# SAMA7G54D1G device description
Architecture: CORTEX-A7; Family: SAMA; Series: SAMA7G
Registers are 32-bit, read-write, reset 0x0 unless marked. A register's access mark holds for its fields unless they carry their own. Offsets are from the block's base; [hi:lo] are bit positions; {n}, {i} and the like mark numbered series.

## SHA — Secure Hash Algorithm
Instances: SHA 0xE1814000
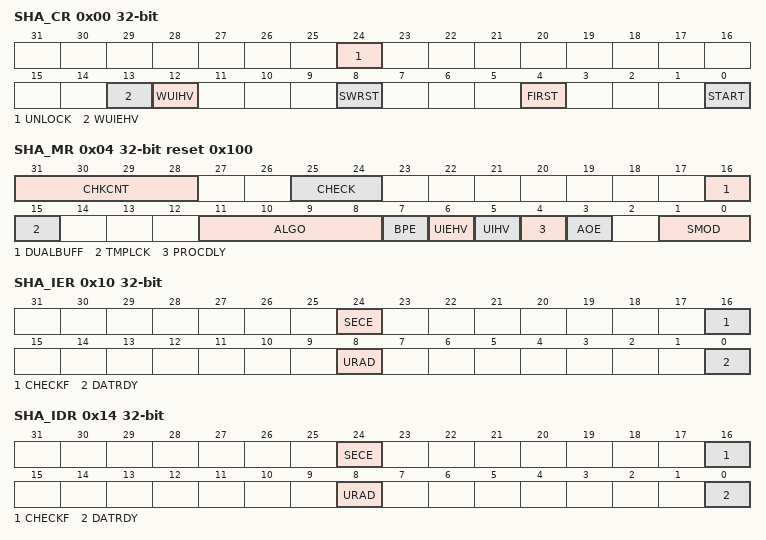
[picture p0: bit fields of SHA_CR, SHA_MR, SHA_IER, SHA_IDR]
0x00 SHA_CR wo reset not defined — Control Register
  [24] UNLOCK — Unlock Processing
    0=No effect; 1=Unlocks the processing in case of abnormal event detection if SHA_WPMR.ACTION > 0
  [13] WUIEHV — Write User Initial or Expected Hash Values
    0=SHA_IDATARx accesses are routed to the data registers; 1=SHA_IDATARx accesses are routed to the internal registers (IR1)
  [12] WUIHV — Write User Initial Hash Values
    0=SHA_IDATARx accesses are routed to the data registers; 1=SHA_IDATARx accesses are routed to the internal registers (IR0)
  [8] SWRST — Software Reset
    0=No effect; 1=Resets the SHA. A software-triggered hardware reset of the SHA interface is performed.
  [4] FIRST — First Block of a Message
    0=No effect; 1=Indicates that the next block to process is the first one of a message
  [0] START — Start Processing
    0=No effect; 1=Starts manual hash algorithm process
0x04 SHA_MR reset 0x100 — Mode Register
  [31:28] CHKCNT — Check Counter
  [25:24] CHECK — Hash Check
    0=NO_CHECK (No check is performed); 1=CHECK_EHV (Check is performed with expected hash stored in internal expected hash value registers.); 2=CHECK_MESSAGE (Check is performed with expected hash provided after the message.)
  [16] DUALBUFF — Dual Input Buffer
    0=INACTIVE (SHA_IDATARx and SHA_IODATARx cannot be written during processing of previous block.); 1=ACTIVE (SHA_IDATARx and SHA_IODATARx can be written during processing of previous block when SMOD value = 2. It speeds up the overall runtime of large files.)
  [15] TMPLCK — Tamper Lock Enable
    0=A tamper event has no effect; 1=A tamper event locks the SHA until the tamper root cause is cleared and SHA_CR.UNLOCK is written to 1
  [11:8] ALGO — SHA Algorithm
    0=SHA1 (SHA1 algorithm processed); 1=SHA256 (SHA256 algorithm processed); 2=SHA384 (SHA384 algorithm processed); 3=SHA512 (SHA512 algorithm processed); 4=SHA224 (SHA224 algorithm processed); 5=SHA512_224 (SHA512/224 algorithm processed); 6=SHA512_256 (SHA512/256 algorithm processed); 8=HMAC_SHA1 (HMAC algorithm with SHA1 Hash processed); 9=HMAC_SHA256 (HMAC algorithm with SHA256 Hash processed); 10=HMAC_SHA384 (HMAC algorithm with SHA384 Hash processed); 11=HMAC_SHA512 (HMAC algorithm with SHA512 Hash processed); 12=HMAC_SHA224 (HMAC algorithm with SHA224 Hash processed); 13=HMAC_SHA512_224 (HMAC algorithm with SHA512/224 Hash processed); 14=HMAC_SHA512_256 (HMAC algorithm with SHA512/256 Hash processed)
  [7] BPE — Block Processing End
    0=BPE must be cleared when a DMA transfers data. When SMOD=2, SHA_ISR.DATRDY flag rises only when the SHA or HMAC processing cycle has completed. No intermediate block processing is reported.; 1=When processing small messages, data transfer by software can improve performance compared to DMA. In this case, BPE can be written to 1, forcing the SHA_ISR.DATRDY to rise when a data must be loaded into SHA_IDATARx.
  [6] UIEHV — User Initial or Expected Hash Value Registers
    0=The SHA algorithm is started with the standard initial values as defined in the FIPS180-2 specification; 1=The SHA algorithm is started with the user initial hash values stored in the internal register 1 (IR1). If HMAC is configured, UIEHV has no effect (i.e. IR1 is always selected).
  [5] UIHV — User Initial Hash Value Registers
    0=The SHA algorithm is started with the standard initial values as defined in the FIPS180-2 specification; 1=The SHA algorithm is started with the user initial hash values stored in the internal register 0 (IR0). If HMAC is configured, UIHV has no effect (i.e. IR0 is selected).
  [4] PROCDLY — Processing Delay
    0=SHORTEST (SHA processing runtime is the shortest one); 1=LONGEST (SHA processing runtime is the longest one (reduces the SHA bandwidth requirement, reduces the system bus overload))
  [3] AOE — Always ON Enable
    0=The SHA operates in functional operating modes; 1=As soon as a START command is written, the SHA processes dummy calculations until AOE=0, without software intervention. This can be used to create an additional current consumption when AES is used to encrypt/decrypt.
  [1:0] SMOD — Start Mode
    0=MANUAL_START (Manual mode); 1=AUTO_START (Auto mode); 2=IDATAR0_START (SHA_IDATAR0 access only mode (mandatory when DMA is used))
0x10 SHA_IER wo reset not defined (atomic set of SHA_IMR) — Interrupt Enable Register
  [24] SECE — Security and/or Safety Event Interrupt Enable
  [16] CHECKF — Check Done Interrupt Enable
  [8] URAD — Unspecified Register Access Detection Interrupt Enable
  [0] DATRDY — Data Ready Interrupt Enable
0x14 SHA_IDR wo reset not defined (atomic clear of SHA_IMR) — Interrupt Disable Register
  [24] SECE — Security and/or Safety Event Interrupt Disable
  [16] CHECKF — Check Done Interrupt Disable
  [8] URAD — Unspecified Register Access Detection Interrupt Disable
  [0] DATRDY — Data Ready Interrupt Disable
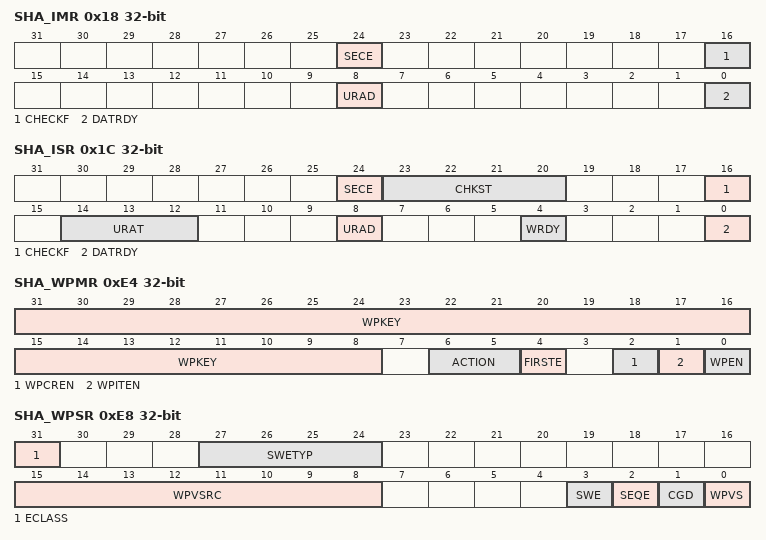
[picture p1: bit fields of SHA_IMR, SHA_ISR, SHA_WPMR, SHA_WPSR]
0x18 SHA_IMR ro — Interrupt Mask Register
  [24] SECE — Security and/or Safety Event Interrupt Mask
  [16] CHECKF — Check Done Interrupt Mask
  [8] URAD — Unspecified Register Access Detection Interrupt Mask
  [0] DATRDY — Data Ready Interrupt Mask
0x1C SHA_ISR ro — Interrupt Status Register
  [24] SECE — Security and/or Safety Event
    0=There is no report in SHA_WPSR; 1=There is a Security and/or Safety Event reported in SHA_WPSR
  [23:20] CHKST — Check Status (cleared by writing START or SWRST bits in SHA_CR or by reading SHA_IODATARx)
  [16] CHECKF — Check Done Status (cleared by writing START or SWRST bits in SHA_CR or by reading SHA_IODATARx)
    0=Hash check has not been computed; 1=Hash check has been computed, status is available in the CHKST bits
  [14:12] URAT — Unspecified Register Access Type (cleared by writing a 1 to SWRST bit in SHA_CR)
  [8] URAD — Unspecified Register Access Detection Status (cleared by writing a 1 to SWRST bit in SHA_CR)
    0=No unspecified register access has been detected since the last SWRST; 1=At least one unspecified register access has been detected since the last SWRST
  [4] WRDY — Input Data Register Write Ready
    0=SHA_IDATAR0 cannot be written; 1=SHA_IDATAR0 can be written
  [0] DATRDY — Data Ready (cleared by writing a 1 to bit SWRST or START in SHA_CR, or by reading SHA_IODATARx)
    0=Output data is not valid; 1=512/1024-bit block process is completed
0x20 SHA_MSR — Message Size Register
  [31:0] MSGSIZE — Message Size
0x30 SHA_BCR — Bytes Count Register
  [31:0] BYTCNT — Remaining Byte Count Before Auto Padding
{0x40+4i} SHA_IDATAR[{i}] (i=0..15) wo reset not defined — Input Data x Register
  [31:0] IDATA — Input Data
{0x80+4i} SHA_IODATAR[{i}] (i=0..15) — Input/Output Data x Register
  [31:0] IODATA — Input/Output Data
0xE4 SHA_WPMR — Write Protection Mode Register
  [31:8] WPKEY — Write Protection Key
    0x534841=PASSWD (Writing any other value in this field aborts the write operation of the WPEN,WPITEN,WPCREN bits. Always reads as 0.)
  [6:5] ACTION — Action on Abnormal Event Detection
    0=REPORT_ONLY (No action (stop or clear key) is performed when one of WPVS,CGD,SEQE, or SWE flag is set.); 1=LOCK_WPVS_SWE (If a processing is in progress when the SHA_WPSR.WPVS/SWE event detection occurs, the current processing is ended normally but no other processing is started while a SHA_CR.UNLOCK command is issued.); 2=LOCK_CGD_SEQE (If a processing is in progress when the SHA_WPSR.CGD/SEQE event detection occurs, the current processing is ended normally but no other processing is started while a SHA_CR.UNLOCK command is issued.); 3=LOCK_ANY_EV (If a processing is in progress when the SHA_WPSR.WPVS/CGD/SEQE/SWE events detection occurs, the current processing is ended normally but no other processing is started while a SHA_CR.UNLOCK command is issued.)
  [4] FIRSTE — First Error Report Enable
    0=The last write protection violation source is reported in SHA_WPSR.WPVSRC and the last software control error type is reported in SHA_WPSR.SWETYP. The SHA_ISR.SECE flag is set at the first error occurrence within a series.; 1=Only the first write protection violation source is reported in SHA_WPSR.WPVSRC and only the first software control error type is reported in SHA_WPSR.SWETYP. The SHA_ISR.SECE flag is set at the first error occurrence within a series.
  [2] WPCREN — Write Protection Control Enable
    0=Disables the write protection on control register if WPKEY corresponds to 0x534841 ("SHA" in ASCII); 1=Enables the write protection on control register if WPKEY corresponds to 0x534841 ("SHA" in ASCII)
  [1] WPITEN — Write Protection Interruption Enable
    0=Disables the write protection on interrupt registers if WPKEY corresponds to 0x534841 ("SHA" in ASCII); 1=Enables the write protection on interrupt registers if WPKEY corresponds to 0x534841 ("SHA" in ASCII)
  [0] WPEN — Write Protection Configuration Enable
    0=Disables the write protection on configuration registers if WPKEY corresponds to 0x534841 ("SHA" in ASCII); 1=Enables the write protection on configuration registers if WPKEY corresponds to 0x534841 ("SHA" in ASCII)
0xE8 SHA_WPSR ro — Write Protection Status Register
  [31] ECLASS — Software Error Class (cleared on read)
    0=WARNING (An abnormal access that does not affect system functionality); 1=ERROR (An access is performed into key, input data, control registers while the SHA is performing an encryption/decryption or a start is request by software or DMA while the key is not fully configured.)
  [27:24] SWETYP — Software Error Type (cleared on read)
    0=READ_WO (A write-only register has been read (Warning).); 1=WRITE_RO (SHA is enabled and a write access has been performed on a read-only register (Warning).); 2=UNDEF_RW (Access to an undefined address (Warning).); 3=CTRL_START (SHA is locked and a start command with SHA_CR.START has been performed.); 4=AUTO_START (SHA is locked and a tentative automatic start has been performed by writing input data registers (SHA_MR.SMOD>0).); 5=BAD_START (SHA is not locked and a start command with SHA_CR.START has been performed whereas Start mode is automatic (SHA_MR.SMOD>0))
  [15:8] WPVSRC — Write Protection Violation Source
  [3] SWE — Software Control Error (cleared on read)
    0=No software error has occurred since the last read of SHA_WPSR; 1=A software error has occurred since the last read of SHA_WPSR. The field SWETYP details the type of software error; the associated incorrect software access is reported in the field WPVSRC (if WPVS=0).
  [2] SEQE — Internal Sequencer Error (cleared on read)
    0=No peripheral internal sequencer error has occurred since the last read of SHA_WPSR; 1=A peripheral internal sequencer error has occurred since the last read of SHA_WPSR. This flag can only be set under abnormal operating conditions.
  [1] CGD — Clock Glitch Detected (cleared on read)
    0=The clock monitoring circuitry has not been corrupted since the last read of SHA_WPSR. Under normal operating conditions, this bit is always cleared.; 1=The clock monitoring circuitry has been corrupted since the last read of SHA_WPSR. This flag can only be set in case of an abnormal clock signal waveform (glitch).
  [0] WPVS — Write Protection Violation Status (cleared on read)
    0=No write protect violation has occurred since the last read of SHA_WPSR; 1=A write protect violation has occurred since the last read of SHA_WPSR. The address offset of the violated register is reported into field WPVSRC.
